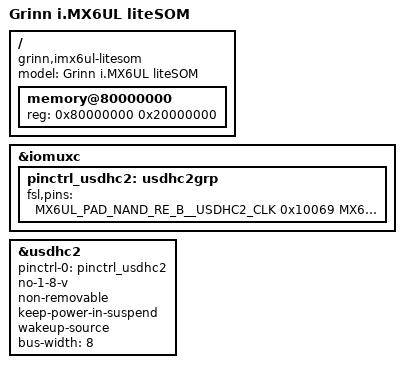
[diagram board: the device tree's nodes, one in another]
// SPDX-License-Identifier: (GPL-2.0-only OR MIT)
/*
 * Copyright 2016 Grinn
 *
 * Author: Marcin Niestroj <m.niestroj@grinn-global.com>
 */

#include "imx6ul.dtsi"

/ {
	model = "Grinn i.MX6UL liteSOM";
	compatible = "grinn,imx6ul-litesom", "fsl,imx6ul";

	memory@80000000 {
		device_type = "memory";
		reg = <0x80000000 0x20000000>;
	};
};

&iomuxc {
	pinctrl_usdhc2: usdhc2grp {
		fsl,pins = <
			MX6UL_PAD_NAND_RE_B__USDHC2_CLK	    0x10069
			MX6UL_PAD_NAND_WE_B__USDHC2_CMD	    0x17059
			MX6UL_PAD_NAND_DATA00__USDHC2_DATA0 0x17059
			MX6UL_PAD_NAND_DATA01__USDHC2_DATA1 0x17059
			MX6UL_PAD_NAND_DATA02__USDHC2_DATA2 0x17059
			MX6UL_PAD_NAND_DATA03__USDHC2_DATA3 0x17059
			MX6UL_PAD_NAND_DATA04__USDHC2_DATA4 0x17059
			MX6UL_PAD_NAND_DATA05__USDHC2_DATA5 0x17059
			MX6UL_PAD_NAND_DATA06__USDHC2_DATA6 0x17059
			MX6UL_PAD_NAND_DATA07__USDHC2_DATA7 0x17059
			MX6UL_PAD_NAND_ALE__USDHC2_RESET_B  0x17059
		>;
	};
};

&usdhc2 {
	pinctrl-names = "default";
	pinctrl-0 = <&pinctrl_usdhc2>;
	no-1-8-v;
	non-removable;
	keep-power-in-suspend;
	wakeup-source;
	bus-width = <8>;
	status = "okay";
};
